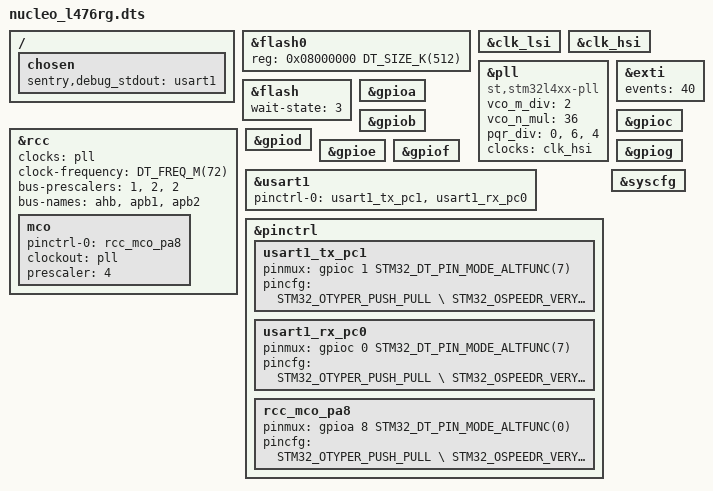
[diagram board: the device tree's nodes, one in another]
/*
 * Copyright (c) 2023,Ledger SAS
 *
 * SPDX-License-Identifier: Apache-2.0
 */

/dts-v1/;

#include <st/l4/stm32l476Xg.dtsi>
#include <dt-bindings/pinctrl/stm32-pinctrl.h>
#include <sentry.dtsi>

/{
	chosen {
		sentry,debug_stdout = <&usart1>;
	};

};

&flash0 {
	reg = <0x08000000 DT_SIZE_K(512)>;
};

&clk_lsi {
	status = "okay";
};

&clk_hsi {
	status = "okay";
};

&pll {
	vco_m_div = <2>;
	vco_n_mul = <36>;
	pqr_div = <0>, <6>, <4>;
	clocks = <&clk_hsi>;
	status = "okay";
	compatible = "st,stm32l4xx-pll";
};

&flash {
	wait-state = <3>; /* According to voltage supply and sysclock */
	status = "okay";
};

&exti {
	events = <40>;
	status = "okay";
};

&rcc {
	clocks = <&pll>;
	clock-frequency = <DT_FREQ_M(72)>;
	bus-prescalers = <1>, <2>, <2>;
	bus-names = "ahb", "apb1", "apb2";
	status = "okay";

	mco {
		pinctrl-0 = <&rcc_mco_pa8>;
		clockout = <&pll>; /* XXX use reg value from svd */
		prescaler = <4>;
		status = "okay";
	};
};

&gpioa {
	status = "okay";
};

&gpiob {
	status = "okay";
};

&gpioc {
	status = "okay";
};

&gpiod {
	status = "okay";
};

&gpioe {
	status = "okay";
};

&gpiof {
	status = "okay";
};

&gpiog {
	status = "okay";
};

&usart1 {
	status = "okay";
	pinctrl-0 = <&usart1_tx_pc1>, <&usart1_rx_pc0>;
};

&pinctrl {
	usart1_tx_pc1: usart1_tx_pc1  {
		pinmux = <&gpioc 1 STM32_DT_PIN_MODE_ALTFUNC(7)>;
		pincfg = <STM32_OTYPER_PUSH_PULL \
				  STM32_OSPEEDR_VERY_HIGH_SPEED \
				  STM32_PUPDR_NO_PULL>;
	};

	usart1_rx_pc0: usart1_rx_pc0  {
		pinmux = <&gpioc 0 STM32_DT_PIN_MODE_ALTFUNC(7)>;
		pincfg = <STM32_OTYPER_PUSH_PULL \
				  STM32_OSPEEDR_VERY_HIGH_SPEED \
				  STM32_PUPDR_NO_PULL>;
	};

	rcc_mco_pa8: rcc_mco_pa8  {
		pinmux = <&gpioa 8 STM32_DT_PIN_MODE_ALTFUNC(0)>;
		pincfg = <STM32_OTYPER_PUSH_PULL \
				  STM32_OSPEEDR_VERY_HIGH_SPEED \
				  STM32_PUPDR_NO_PULL>;
	};
};

&syscfg {
	status = "okay";
};
